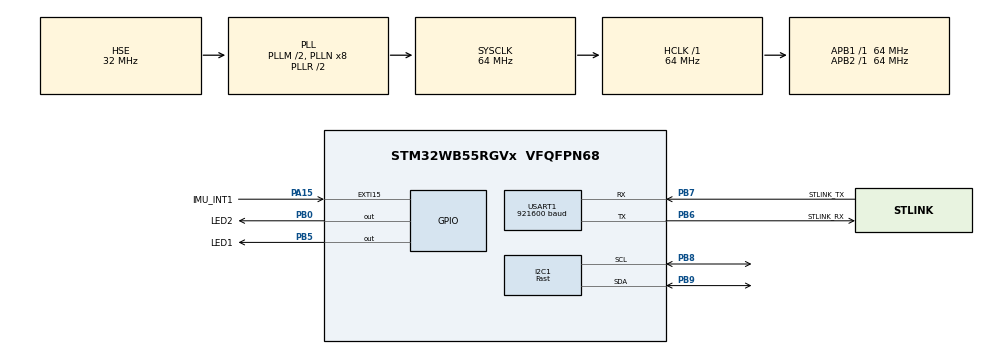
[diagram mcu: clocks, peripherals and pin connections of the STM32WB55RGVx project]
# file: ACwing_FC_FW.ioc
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Dma.I2C1_RX.0.Direction=DMA_PERIPH_TO_MEMORY
Dma.I2C1_RX.0.EventEnable=DISABLE
Dma.I2C1_RX.0.Instance=DMA1_Channel1
Dma.I2C1_RX.0.MemDataAlignment=DMA_MDATAALIGN_BYTE
Dma.I2C1_RX.0.MemInc=DMA_MINC_ENABLE
Dma.I2C1_RX.0.Mode=DMA_NORMAL
Dma.I2C1_RX.0.PeriphDataAlignment=DMA_PDATAALIGN_BYTE
Dma.I2C1_RX.0.PeriphInc=DMA_PINC_DISABLE
Dma.I2C1_RX.0.Polarity=HAL_DMAMUX_REQ_GEN_RISING
Dma.I2C1_RX.0.Priority=DMA_PRIORITY_LOW
Dma.I2C1_RX.0.RequestNumber=1
Dma.I2C1_RX.0.SignalID=NONE
Dma.I2C1_RX.0.SyncEnable=DISABLE
Dma.I2C1_RX.0.SyncPolarity=HAL_DMAMUX_SYNC_NO_EVENT
Dma.I2C1_RX.0.SyncRequestNumber=1
Dma.I2C1_RX.0.SyncSignalID=NONE
Dma.Request0=I2C1_RX
Dma.Request1=USART1_TX
Dma.USART1_TX.1.Direction=DMA_MEMORY_TO_PERIPH
Dma.USART1_TX.1.EventEnable=DISABLE
Dma.USART1_TX.1.Instance=DMA1_Channel2
Dma.USART1_TX.1.MemDataAlignment=DMA_MDATAALIGN_BYTE
Dma.USART1_TX.1.MemInc=DMA_MINC_ENABLE
Dma.USART1_TX.1.Mode=DMA_NORMAL
Dma.USART1_TX.1.PeriphDataAlignment=DMA_PDATAALIGN_BYTE
Dma.USART1_TX.1.PeriphInc=DMA_PINC_DISABLE
Dma.USART1_TX.1.Polarity=HAL_DMAMUX_REQ_GEN_RISING
Dma.USART1_TX.1.Priority=DMA_PRIORITY_LOW
Dma.USART1_TX.1.RequestNumber=1
Dma.USART1_TX.1.SignalID=NONE
Dma.USART1_TX.1.SyncEnable=DISABLE
Dma.USART1_TX.1.SyncPolarity=HAL_DMAMUX_SYNC_NO_EVENT
Dma.USART1_TX.1.SyncRequestNumber=1
Dma.USART1_TX.1.SyncSignalID=NONE
FREERTOS.Tasks01=defaultTask,24,128,StartDefaultTask,Default,NULL,Dynamic,NULL,NULL
FREERTOS.configCHECK_FOR_STACK_OVERFLOW=2
FREERTOS.configENABLE_FPU=1
FREERTOS.configLIBRARY_MAX_SYSCALL_INTERRUPT_PRIORITY=5
FREERTOS.configTOTAL_HEAP_SIZE=52000
FREERTOS.configUSE_NEWLIB_REENTRANT=1
I2C1.I2C_Speed_Mode=I2C_Fast
I2C1.Timing=0x00C12166
Mcu.Family=STM32WB
Mcu.Name=STM32WB55RGVx
Mcu.Package=VFQFPN68
NVIC.DMA1_Channel1_IRQn=true\:6\:0\:true\:false\:true\:true\:false\:true\:true
NVIC.DMA1_Channel2_IRQn=true\:7\:0\:true\:false\:true\:true\:false\:true\:true
NVIC.EXTI15_10_IRQn=true\:5\:0\:true\:false\:true\:true\:true\:true\:true
NVIC.HSEM_IRQn=true\:5\:0\:false\:false\:true\:true\:false\:true\:true
NVIC.I2C1_ER_IRQn=true\:6\:0\:true\:false\:true\:true\:true\:true\:true
NVIC.I2C1_EV_IRQn=true\:6\:0\:true\:false\:true\:true\:true\:true\:true
NVIC.IPCC_C1_RX_IRQn=true\:5\:0\:false\:false\:true\:true\:true\:true\:true
NVIC.IPCC_C1_TX_IRQn=true\:5\:0\:false\:false\:true\:true\:true\:true\:true
NVIC.PriorityGroup=NVIC_PRIORITYGROUP_4
NVIC.RNG_IRQn=true\:5\:0\:false\:false\:true\:true\:true\:true\:true
NVIC.RTC_WKUP_IRQn=true\:5\:0\:false\:false\:true\:true\:true\:true\:true
NVIC.TIM1_TRG_COM_TIM17_IRQn=true\:15\:0\:false\:false\:true\:false\:false\:true\:true
NVIC.TimeBase=TIM1_TRG_COM_TIM17_IRQn
NVIC.TimeBaseIP=TIM17
NVIC.USART1_IRQn=true\:7\:0\:true\:false\:true\:true\:true\:true\:true
OSC_IN.GPIO_Label=RCC_OSC_IN
OSC_IN.Mode=HSE-External-Oscillator
OSC_IN.Signal=RCC_OSC_IN
OSC_OUT.GPIO_Label=RCC_OSC_OUT
OSC_OUT.Mode=HSE-External-Oscillator
OSC_OUT.Signal=RCC_OSC_OUT
PA11.GPIO_Label=USB_DM
PA11.Signal=USB_DM
PA12.GPIO_Label=USB_DP
PA12.Signal=USB_DP
PA13.GPIO_Label=JTMS
PA13.Mode=Serial_Wire
PA13.Signal=SYS_JTMS-SWDIO
PA14.GPIO_Label=JTCK
PA14.Mode=Serial_Wire
PA14.Signal=SYS_JTCK-SWCLK
PA15.GPIO_Label=IMU_INT1
PA15.Signal=GPXTI15
PB0.GPIO_Label=LED2
PB0.Signal=GPIO_Output
PB3.GPIO_Label=JTDO
PB3.Signal=SYS_JTDO-SWO
PB5.GPIO_Label=LED1
PB5.Signal=GPIO_Output
PB6.GPIO_Label=STLINK_RX
PB6.Mode=Asynchronous
PB6.Signal=USART1_TX
PB7.GPIO_Label=STLINK_TX
PB7.Mode=Asynchronous
PB7.Signal=USART1_RX
PB8.Mode=I2C
PB8.Signal=I2C1_SCL
PB9.Mode=I2C
PB9.Signal=I2C1_SDA
PC13.GPIO_Label=SYS_WKUP2
PC13.Signal=SYS_WKUP2
PC14-OSC32_IN.GPIO_Label=RCC_OSC32_IN
PC14-OSC32_IN.Mode=LSE-External-Oscillator
PC14-OSC32_IN.Signal=RCC_OSC32_IN
PC15-OSC32_OUT.GPIO_Label=RCC_OSC32_OUT
PC15-OSC32_OUT.Mode=LSE-External-Oscillator
PC15-OSC32_OUT.Signal=RCC_OSC32_OUT
ProjectManager.HeapSize=0x200
ProjectManager.StackSize=0x400
ProjectManager.TargetToolchain=STM32CubeIDE
RCC.ADCFreq_Value=64000000
RCC.AHB2CLKDivider=RCC_SYSCLK_DIV2
RCC.AHBFreq_Value=64000000
RCC.APB1Freq_Value=64000000
RCC.APB1TimFreq_Value=64000000
RCC.APB2Freq_Value=64000000
RCC.APB2TimFreq_Value=64000000
RCC.APB3Freq_Value=16000000
RCC.CortexFreq_Value=64000000
RCC.HCLKFreq_Value=64000000
RCC.HSE_VALUE=32000000
RCC.HSI48_VALUE=48000000
RCC.HSI_VALUE=16000000
RCC.PLLM=RCC_PLLM_DIV2
RCC.PLLSourceVirtual=RCC_PLLSOURCE_HSE
RCC.RFWKPClockSelection=RCC_RFWKPCLKSOURCE_LSE
RCC.RTCClockSelection=RCC_RTCCLKSOURCE_LSE
RCC.SMPSCLockSelection=RCC_SMPSCLKSOURCE_HSI
RCC.SMPSCLockSelectionVirtual=RCC_SMPSCLKSOURCE_HSI
RCC.SMPSCLockSelectionVirtualVirtual=RCC_SMPSCLKSOURCE_HSI
RCC.SMPSDivider=1
RCC.SYSCLKFreq_VALUE=64000000
RCC.SYSCLKSource=RCC_SYSCLKSOURCE_PLLCLK
RCC.USBFreq_Value=64000000
RCC.VCOOutputFreq_Value=128000000
RF1.Mode=RF1_Activate
RF1.Signal=RF_RF1
STM32_WPAN.BT_SIG_HEART_RATE_SENSOR=Enabled
STM32_WPAN.CFG_BLE_MAX_ATT_MTU=247
STM32_WPAN.CFG_LSCLK_LSE=0
STM32_WPAN.LOCAL_NAME=ACwFC
STM32_WPAN.LOCAL_NAME_FORMATTED=,'A','C','w','F','C'
USART1.BaudRate=921600
USART1.VirtualMode-Asynchronous=VM_ASYNC
VP_FREERTOS_VS_CMSIS_V2.Mode=CMSIS_V2
VP_HSEM_VS_HSEM.Mode=HSEM_Activate
VP_IPCC_VS_IPCC.Mode=IPCC_Activate
VP_MEMORYMAP_VS_MEMORYMAP.Mode=CurAppReg
VP_RNG_VS_RNG.Mode=RNG_Activate
VP_RTC_VS_RTC_Activate.Mode=RTC_Enabled
VP_RTC_VS_RTC_WakeUp_intern.Mode=WakeUp
VP_STM32_WPAN_VS_BLE_HOST.Mode=STM32_WPAN_Enabled
VP_SYS_VS_tim17.Mode=TIM17
VP_TINY_LPM_VS_TINY_LPM.Mode=TINY_LPM_Enabled
board=P-NUCLEO-WB55-NUCLEO

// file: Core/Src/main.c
/* USER CODE BEGIN Header */
/**
  ******************************************************************************
  * @file           : main.c
  * @brief          : Main program body
  ******************************************************************************
  * @attention
  *
  * Copyright (c) 2026 STMicroelectronics.
  * All rights reserved.
  *
  * This software is licensed under terms that can be found in the LICENSE file
  * in the root directory of this software component.
  * If no LICENSE file comes with this software, it is provided AS-IS.
  *
  ******************************************************************************
  */
/* USER CODE END Header */
#include "main.h"
#include "cmsis_os2.h"
#include "FreeRTOS.h"

/* USER CODE BEGIN Includes */
#include "app_main.h"
/* USER CODE END Includes */

I2C_HandleTypeDef hi2c1;
DMA_HandleTypeDef hdma_i2c1_rx;

IPCC_HandleTypeDef hipcc;

RNG_HandleTypeDef hrng;

RTC_HandleTypeDef hrtc;

UART_HandleTypeDef huart1;
DMA_HandleTypeDef hdma_usart1_tx;

/* Definitions for defaultTask */
osThreadId_t defaultTaskHandle;
const osThreadAttr_t defaultTask_attributes = {
  .name = "defaultTask",
  .priority = (osPriority_t) osPriorityNormal,
  .stack_size = 128 * 4
};

void SystemClock_Config(void);
void PeriphCommonClock_Config(void);
static void MX_GPIO_Init(void);
static void MX_DMA_Init(void);
static void MX_I2C1_Init(void);
static void MX_USART1_UART_Init(void);
static void MX_IPCC_Init(void);
static void MX_RTC_Init(void);
static void MX_RNG_Init(void);
static void MX_RF_Init(void);
void StartDefaultTask(void *argument);

int main(void)
{

  /* MCU Configuration--------------------------------------------------------*/

  /* Reset of all peripherals, Initializes the Flash interface and the Systick. */
  HAL_Init();
  /* Config code for STM32_WPAN (HSE Tuning must be done before system clock configuration) */
  MX_APPE_Config();

  /* Configure the system clock */
  SystemClock_Config();

  /* Configure the peripherals common clocks */
  PeriphCommonClock_Config();

  /* IPCC initialisation */
  MX_IPCC_Init();

  /* Initialize all configured peripherals */
  MX_GPIO_Init();
  MX_DMA_Init();
  MX_I2C1_Init();
  MX_USART1_UART_Init();
  MX_RTC_Init();
  MX_RNG_Init();
  MX_RF_Init();

  /* Init scheduler */
  osKernelInitialize();

  /* Create the thread(s) */
  /* creation of defaultTask */
  defaultTaskHandle = osThreadNew(StartDefaultTask, NULL, &defaultTask_attributes);

  /* USER CODE BEGIN RTOS_THREADS */
  /* add threads, ... */
  app_start();
  /* USER CODE END RTOS_THREADS */

  /* Init code for STM32_WPAN */
  MX_APPE_Init();

  /* Start scheduler */
  osKernelStart();

  /* We should never get here as control is now taken by the scheduler */

  /* Infinite loop */
  while (1)
  {

  }
}

void SystemClock_Config(void)
{
  RCC_OscInitTypeDef RCC_OscInitStruct = {0};
  RCC_ClkInitTypeDef RCC_ClkInitStruct = {0};

  /** Configure LSE Drive Capability
  */
  HAL_PWR_EnableBkUpAccess();
  __HAL_RCC_LSEDRIVE_CONFIG(RCC_LSEDRIVE_MEDIUMHIGH);

  /** Configure the main internal regulator output voltage
  */
  __HAL_PWR_VOLTAGESCALING_CONFIG(PWR_REGULATOR_VOLTAGE_SCALE1);

  /** Initializes the RCC Oscillators according to the specified parameters
  * in the RCC_OscInitTypeDef structure.
  */
  RCC_OscInitStruct.OscillatorType = RCC_OSCILLATORTYPE_HSI|RCC_OSCILLATORTYPE_LSI1
                              |RCC_OSCILLATORTYPE_HSE|RCC_OSCILLATORTYPE_LSE;
  RCC_OscInitStruct.HSEState = RCC_HSE_ON;
  RCC_OscInitStruct.LSEState = RCC_LSE_ON;
  RCC_OscInitStruct.HSIState = RCC_HSI_ON;
  RCC_OscInitStruct.HSICalibrationValue = RCC_HSICALIBRATION_DEFAULT;
  RCC_OscInitStruct.LSIState = RCC_LSI_ON;
  RCC_OscInitStruct.PLL.PLLState = RCC_PLL_ON;
  RCC_OscInitStruct.PLL.PLLSource = RCC_PLLSOURCE_HSE;
  RCC_OscInitStruct.PLL.PLLM = RCC_PLLM_DIV2;
  RCC_OscInitStruct.PLL.PLLN = 8;
  RCC_OscInitStruct.PLL.PLLP = RCC_PLLP_DIV2;
  RCC_OscInitStruct.PLL.PLLR = RCC_PLLR_DIV2;
  RCC_OscInitStruct.PLL.PLLQ = RCC_PLLQ_DIV2;
  if (HAL_RCC_OscConfig(&RCC_OscInitStruct) != HAL_OK)
  {
    Error_Handler();
  }

  /** Configure the SYSCLKSource, HCLK, PCLK1 and PCLK2 clocks dividers
  */
  RCC_ClkInitStruct.ClockType = RCC_CLOCKTYPE_HCLK4|RCC_CLOCKTYPE_HCLK2
                              |RCC_CLOCKTYPE_HCLK|RCC_CLOCKTYPE_SYSCLK
                              |RCC_CLOCKTYPE_PCLK1|RCC_CLOCKTYPE_PCLK2;
  RCC_ClkInitStruct.SYSCLKSource = RCC_SYSCLKSOURCE_PLLCLK;
  RCC_ClkInitStruct.AHBCLKDivider = RCC_SYSCLK_DIV1;
  RCC_ClkInitStruct.APB1CLKDivider = RCC_HCLK_DIV1;
  RCC_ClkInitStruct.APB2CLKDivider = RCC_HCLK_DIV1;
  RCC_ClkInitStruct.AHBCLK2Divider = RCC_SYSCLK_DIV2;
  RCC_ClkInitStruct.AHBCLK4Divider = RCC_SYSCLK_DIV1;

  if (HAL_RCC_ClockConfig(&RCC_ClkInitStruct, FLASH_LATENCY_3) != HAL_OK)
  {
    Error_Handler();
  }
}

void PeriphCommonClock_Config(void)
{
  RCC_PeriphCLKInitTypeDef PeriphClkInitStruct = {0};

  /** Initializes the peripherals clock
  */
  PeriphClkInitStruct.PeriphClockSelection = RCC_PERIPHCLK_SMPS|RCC_PERIPHCLK_RFWAKEUP;
  PeriphClkInitStruct.RFWakeUpClockSelection = RCC_RFWKPCLKSOURCE_LSE;
  PeriphClkInitStruct.SmpsClockSelection = RCC_SMPSCLKSOURCE_HSI;
  PeriphClkInitStruct.SmpsDivSelection = RCC_SMPSCLKDIV_RANGE0;

  if (HAL_RCCEx_PeriphCLKConfig(&PeriphClkInitStruct) != HAL_OK)
  {
    Error_Handler();
  }
}

static void MX_I2C1_Init(void)
{

  hi2c1.Instance = I2C1;
  hi2c1.Init.Timing = 0x00C12166;
  hi2c1.Init.OwnAddress1 = 0;
  hi2c1.Init.AddressingMode = I2C_ADDRESSINGMODE_7BIT;
  hi2c1.Init.DualAddressMode = I2C_DUALADDRESS_DISABLE;
  hi2c1.Init.OwnAddress2 = 0;
  hi2c1.Init.OwnAddress2Masks = I2C_OA2_NOMASK;
  hi2c1.Init.GeneralCallMode = I2C_GENERALCALL_DISABLE;
  hi2c1.Init.NoStretchMode = I2C_NOSTRETCH_DISABLE;
  if (HAL_I2C_Init(&hi2c1) != HAL_OK)
  {
    Error_Handler();
  }

  /** Configure Analogue filter
  */
  if (HAL_I2CEx_ConfigAnalogFilter(&hi2c1, I2C_ANALOGFILTER_ENABLE) != HAL_OK)
  {
    Error_Handler();
  }

  /** Configure Digital filter
  */
  if (HAL_I2CEx_ConfigDigitalFilter(&hi2c1, 0) != HAL_OK)
  {
    Error_Handler();
  }

}

static void MX_IPCC_Init(void)
{

  hipcc.Instance = IPCC;
  if (HAL_IPCC_Init(&hipcc) != HAL_OK)
  {
    Error_Handler();
  }

}

static void MX_RF_Init(void)
{

}

static void MX_RNG_Init(void)
{

  hrng.Instance = RNG;
  hrng.Init.ClockErrorDetection = RNG_CED_ENABLE;
  if (HAL_RNG_Init(&hrng) != HAL_OK)
  {
    Error_Handler();
  }

}

static void MX_RTC_Init(void)
{

  /** Initialize RTC Only
  */
  hrtc.Instance = RTC;
  hrtc.Init.HourFormat = RTC_HOURFORMAT_24;
  hrtc.Init.AsynchPrediv = CFG_RTC_ASYNCH_PRESCALER;
  hrtc.Init.SynchPrediv = CFG_RTC_SYNCH_PRESCALER;
  hrtc.Init.OutPut = RTC_OUTPUT_DISABLE;
  hrtc.Init.OutPutPolarity = RTC_OUTPUT_POLARITY_HIGH;
  hrtc.Init.OutPutType = RTC_OUTPUT_TYPE_OPENDRAIN;
  hrtc.Init.OutPutRemap = RTC_OUTPUT_REMAP_NONE;
  if (HAL_RTC_Init(&hrtc) != HAL_OK)
  {
    Error_Handler();
  }

  /** Enable the WakeUp
  */
  if (HAL_RTCEx_SetWakeUpTimer_IT(&hrtc, 0, RTC_WAKEUPCLOCK_RTCCLK_DIV16) != HAL_OK)
  {
    Error_Handler();
  }

}

static void MX_USART1_UART_Init(void)
{

  huart1.Instance = USART1;
  huart1.Init.BaudRate = 921600;
  huart1.Init.WordLength = UART_WORDLENGTH_8B;
  huart1.Init.StopBits = UART_STOPBITS_1;
  huart1.Init.Parity = UART_PARITY_NONE;
  huart1.Init.Mode = UART_MODE_TX_RX;
  huart1.Init.HwFlowCtl = UART_HWCONTROL_NONE;
  huart1.Init.OverSampling = UART_OVERSAMPLING_16;
  huart1.Init.OneBitSampling = UART_ONE_BIT_SAMPLE_DISABLE;
  huart1.Init.ClockPrescaler = UART_PRESCALER_DIV1;
  huart1.AdvancedInit.AdvFeatureInit = UART_ADVFEATURE_NO_INIT;
  if (HAL_UART_Init(&huart1) != HAL_OK)
  {
    Error_Handler();
  }
  if (HAL_UARTEx_SetTxFifoThreshold(&huart1, UART_TXFIFO_THRESHOLD_1_8) != HAL_OK)
  {
    Error_Handler();
  }
  if (HAL_UARTEx_SetRxFifoThreshold(&huart1, UART_RXFIFO_THRESHOLD_1_8) != HAL_OK)
  {
    Error_Handler();
  }
  if (HAL_UARTEx_DisableFifoMode(&huart1) != HAL_OK)
  {
    Error_Handler();
  }

}

static void MX_DMA_Init(void)
{

  /* DMA controller clock enable */
  __HAL_RCC_DMAMUX1_CLK_ENABLE();
  __HAL_RCC_DMA1_CLK_ENABLE();

  /* DMA interrupt init */
  /* DMA1_Channel1_IRQn interrupt configuration */
  HAL_NVIC_SetPriority(DMA1_Channel1_IRQn, 6, 0);
  HAL_NVIC_EnableIRQ(DMA1_Channel1_IRQn);
  /* DMA1_Channel2_IRQn interrupt configuration */
  HAL_NVIC_SetPriority(DMA1_Channel2_IRQn, 7, 0);
  HAL_NVIC_EnableIRQ(DMA1_Channel2_IRQn);

}

static void MX_GPIO_Init(void)
{
  GPIO_InitTypeDef GPIO_InitStruct = {0};

  /* GPIO Ports Clock Enable */
  __HAL_RCC_GPIOC_CLK_ENABLE();
  __HAL_RCC_GPIOB_CLK_ENABLE();
  __HAL_RCC_GPIOA_CLK_ENABLE();

  /*Configure GPIO pin Output Level */
  HAL_GPIO_WritePin(GPIOB, LED2_Pin|LED1_Pin, GPIO_PIN_RESET);

  /*Configure GPIO pins : LED2_Pin LED1_Pin */
  GPIO_InitStruct.Pin = LED2_Pin|LED1_Pin;
  GPIO_InitStruct.Mode = GPIO_MODE_OUTPUT_PP;
  GPIO_InitStruct.Pull = GPIO_NOPULL;
  GPIO_InitStruct.Speed = GPIO_SPEED_FREQ_LOW;
  HAL_GPIO_Init(GPIOB, &GPIO_InitStruct);

  /*Configure GPIO pins : USB_DM_Pin USB_DP_Pin */
  GPIO_InitStruct.Pin = USB_DM_Pin|USB_DP_Pin;
  GPIO_InitStruct.Mode = GPIO_MODE_AF_PP;
  GPIO_InitStruct.Pull = GPIO_NOPULL;
  GPIO_InitStruct.Speed = GPIO_SPEED_FREQ_LOW;
  GPIO_InitStruct.Alternate = GPIO_AF10_USB;
  HAL_GPIO_Init(GPIOA, &GPIO_InitStruct);

  /*Configure GPIO pin : IMU_INT1_Pin */
  GPIO_InitStruct.Pin = IMU_INT1_Pin;
  GPIO_InitStruct.Mode = GPIO_MODE_IT_RISING;
  GPIO_InitStruct.Pull = GPIO_NOPULL;
  HAL_GPIO_Init(IMU_INT1_GPIO_Port, &GPIO_InitStruct);

  /* EXTI interrupt init*/
  HAL_NVIC_SetPriority(EXTI15_10_IRQn, 5, 0);
  HAL_NVIC_EnableIRQ(EXTI15_10_IRQn);

}

/* USER CODE BEGIN 4 */
void HAL_GPIO_EXTI_Callback(uint16_t pin)            { app_exti(pin); }
void HAL_I2C_MemRxCpltCallback(I2C_HandleTypeDef *h) { app_i2c_rx_cplt(h); }
void HAL_I2C_ErrorCallback(I2C_HandleTypeDef *h)     { app_i2c_error(h); }
void HAL_UART_TxCpltCallback(UART_HandleTypeDef *h)  { app_uart_tx_cplt(h); }
/* USER CODE END 4 */

void StartDefaultTask(void *argument)
{
  for(;;)
  {
    osDelay(1);
  }
}

void HAL_TIM_PeriodElapsedCallback(TIM_HandleTypeDef *htim)
{
  if (htim->Instance == TIM17)
  {
    HAL_IncTick();
  }
}

void Error_Handler(void)
{
  __disable_irq();
  while (1)
  {
  }
}
